# DA14680 register map
Vendor: Dialog; Series: DA14680; File version: 1.2
CPU: CM0 r1p0, little endian, MPU, FPU, 3 interrupt priority bits
Registers are 16-bit, read-write, reset 0x0 unless marked. A register's access mark holds for its fields unless they carry their own. Offsets are from the block's base; lines under a group give offsets from that group; [hi:lo] are bit positions; {n}, {i} and the like mark numbered series; 'fields as' and 'values as' point back to an identical list; <NAME> marks a mode.

## Memory map
0x07F40000 OTPC size 0x30 — OTPC registers
0x0C000000 QSPIC size 0x44 — QSPIC registers
0x40000000 BLE size 0x214 — BLE registers
0x40020000 AES_HASH size 0x104 — AES_HASH registers
0x40080000 FTDF size 0x11008 — FTDF registers
0x400C3000 CACHE size 0x54 — CACHE registers
0x50000000 CRG_TOP size 0x52 — CRG_TOP registers
0x50000080 DCDC size 0x3A — DCDC registers
0x50000100 WAKEUP size 0x1E — WAKEUP registers
0x50000200 TIMER1 size 0x1A — TIMER1 registers
0x50001000 UART size 0x100 — UART registers
0x50001100 UART2 size 0x100 — UART2 registers
0x50001200 SPI size 0xA — SPI registers
0x50001300 SPI2 size 0xA — SPI2 registers
0x50001400 I2C size 0x100 — I2C registers
0x50001500 I2C2 size 0x100 — I2C2 registers
0x50001600 KBSCAN size 0x5C — KBSCAN registers
0x50001700 IR size 0x14 — IR registers
0x50001800 USB size 0xD8 — USB registers
0x50001900 GPADC size 0xE — GPADC registers
0x50001A00 QUAD size 0xA — QUAD registers
0x50001B00 ANAMISC size 0x68 — ANAMISC registers
0x50001C00 CRG_PER size 0x4C — CRG_PER registers
0x50002F00 COEX size 0x34 — COEX registers
0x50003000 GPIO size 0xD2 — GPIO registers
0x50003100 WDOG size 0x4 — WDOG registers
0x50003200 CHIP_VERSION size 0x5 — CHIP_VERSION registers
0x50003300 GPREG size 0x1A — GPREG registers
0x50003400 GP_TIMERS size 0x20 — GP_TIMERS registers
0x50003500 DMA size 0x86 — DMA registers
0x50004000 APU size 0x114 — APU registers
0x50005000 TRNG size 0xC — TRNG registers
0x50006000 ECC size 0x14 — ECC registers
0xE000E010 SysTick size 0x11 — Cortex M0 SysTick registers
0xE000E100 NVIC size 0x321 — Cortex M0 NVIC registers
0xE000ED00 SCB size 0x29 — Cortex M0 SCB registers

## Interrupts
0 BLE_WAKEUP_LP (WDOG)
1 BLE_GEN (WDOG)
2 FTDF_WAKEUP (WDOG)
3 FTDF_GEN (WDOG)
4 RFCAL (WDOG)
5 COEX (WDOG)
6 CRYPTO (WDOG)
7 MRM (WDOG)
8 UART (WDOG)
9 UART2 (WDOG)
10 I2C (WDOG)
11 I2C2 (WDOG)
12 SPI (WDOG)
13 SPI2 (WDOG)
14 ADC (WDOG)
15 KEYBRD (WDOG)
16 IRGEN (WDOG)
17 WKUP_GPIO (WDOG)
18 SWTIM0 (WDOG)
19 SWTIM1 (WDOG)
20 QUADEC (WDOG)
21 USB (WDOG)
22 PCM (WDOG)
23 SRC_IN (WDOG)
24 SRC_OUT (WDOG)
25 VBUS (WDOG)
26 DMA (WDOG)
27 RF_DIAG (WDOG)
28 TRNG (WDOG)
29 DCDC (WDOG)
30 XTAL16RDY (WDOG)
31 RESERVED31 (WDOG)

## SCB — Cortex M0 SCB registers
Base 0xE000ED00
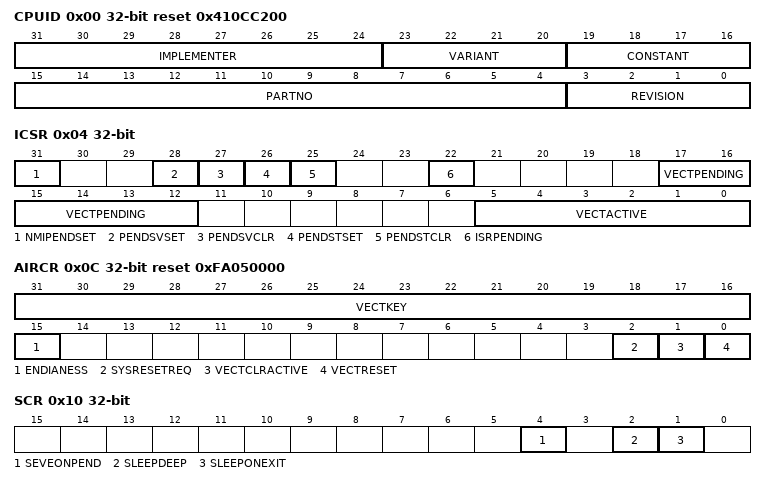
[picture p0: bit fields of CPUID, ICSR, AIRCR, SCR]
0x00 CPUID 32-bit reset 0x410CC200 — CPUID base register
  [31:24] IMPLEMENTER ro — IMPLEMENTER[7:0] bits (Implementer code)
  [23:20] VARIANT ro — VARIANT[3:0] bits (Variant number)
  [19:16] CONSTANT ro — CONSTANT[3:0] bits (Reads as 0xF)
  [15:4] PARTNO ro — PARTNO[11:0] bits (Part number of the processor core)
  [3:0] REVISION ro — REVISION[3:0] bits (Revision number)
0x04 ICSR 32-bit — Interrupt control and state register
  [31] NMIPENDSET — NMI set-pending bit
  [28] PENDSVSET — PendSV set-pending bit
  [27] PENDSVCLR — PendSV clear-pending bit
  [26] PENDSTSET — SysTick exception set-pending bit
  [25] PENDSTCLR — SysTick exception clear-pending bit
  [22] ISRPENDING — Interrupt pending flag, excluding NMI and Faults
  [17:12] VECTPENDING — VECTPENDING[5:0] bits (Pending vector)
  [5:0] VECTACTIVE — VECTACTIVE[5:0] bits (Active vector)
0x0C AIRCR 32-bit ro reset 0xFA050000 — Application interrupt and reset control register
  [31:16] VECTKEY — VECTKEY[15:0] bits (Register key)
  [15] ENDIANESS — Data endianness bit
  [2] SYSRESETREQ — System reset request
  [1] VECTCLRACTIVE — Reserved for Debug use
  [0] VECTRESET — Reserved for Debug use
0x10 SCR 32-bit — System control register
  [4] SEVEONPEND — Send event on pending bit
  [2] SLEEPDEEP — Controls whether the processor uses sleep or deep sleep
  [1] SLEEPONEXIT — Configures sleep-on-exit when returning from Handler mode to Thread mode
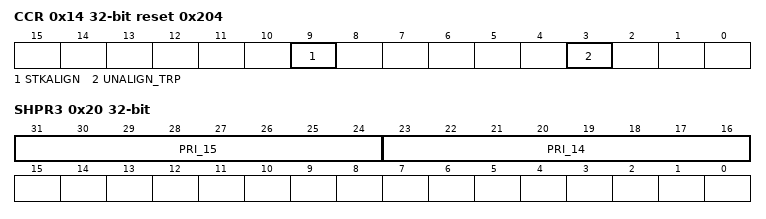
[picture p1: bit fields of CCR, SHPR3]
0x14 CCR 32-bit reset 0x204 — Configuration and control register
  [9] STKALIGN — Configures stack alignment on exception entry
  [3] UNALIGN_TRP — Enables unaligned access traps
0x1C SHPR2 32-bit — System handler priority register 2
  [31:24] PRI_11 — PRI_11[7:0] bits (Priority of system handler 11, SVCall)
0x20 SHPR3 32-bit — System handler priority register 3
  [31:24] PRI_15 — PRI_15[7:0] bits (Priority of system handler 15, SysTick exception)
  [23:16] PRI_14 — PRI_14[7:0] bits (Priority of system handler 14, PendSV)

## Licence text in the file
Copyright (C) 2018 Dialog Semiconductor. This computer program includes Confidential, Proprietary Information of Dialog Semiconductor. All Rights Reserved. . Dialog GmbH (DLG) is supplying this software for use with Cortex-M processor based microcontroller, but can be equally used for other suitable processor architectures. This file can be freely distributed. Modifications to this file shall be clearly marked. . THIS SOFTWARE IS PROVIDED AS IS . NO WARRANTIES, WHETHER EXPRESS, IMPLIED. OR STATUTORY, INCLUDING, BUT NOT LIMITED TO, IMPLIED WARRANTIES OF. MERCHANTABILITY AND FITNESS FOR A PARTICULAR PURPOSE APPLY TO THIS SOFTWARE. ARM SHALL NOT, IN ANY CIRCUMSTANCES, BE LIABLE FOR SPECIAL, INCIDENTAL, OR. CONSEQUENTIAL DAMAGES, FOR ANY REASON WHATSOEVER.
